VERSION ""

NS_ :

BS_:

BU_: XXX

BO_ 85 CID_LXWGIO: 8 XXX
 SG_ sig_nwyayb : 40|1@1+ (1,0) [0|1] "" XXX
 SG_ sig_ymgcwg : 56|8@1+ (1,0) [0|255] "" XXX

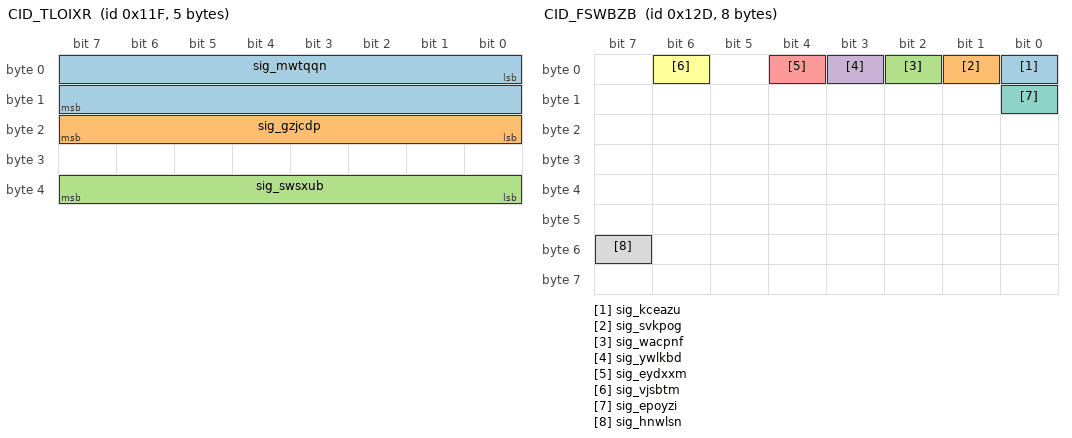
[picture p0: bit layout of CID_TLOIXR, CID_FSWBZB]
BO_ 287 CID_TLOIXR: 5 XXX
 SG_ sig_mwtqqn : 0|16@1- (0.1,0) [-450|450] "" XXX
 SG_ sig_gzjcdp : 16|8@1+ (4,0) [0|1020] "" XXX
 SG_ sig_swsxub : 32|8@1+ (1,0) [0|255] "" XXX

BO_ 289 CID_BDCPJX: 8 XXX
 SG_ sig_shysqb : 0|12@1+ (1,0) [0|255] "" XXX

BO_ 301 CID_FSWBZB: 8 XXX
 SG_ sig_kceazu : 0|1@0+ (1,0) [0|1] "" XXX
 SG_ sig_svkpog : 1|1@0+ (1,0) [0|1] "" XXX
 SG_ sig_wacpnf : 2|1@0+ (1,0) [0|1] "" XXX
 SG_ sig_ywlkbd : 3|1@0+ (1,0) [0|1] "" XXX
 SG_ sig_eydxxm : 4|1@0+ (1,0) [0|1] "" XXX
 SG_ sig_vjsbtm : 6|1@0+ (1,0) [0|1] "" XXX
 SG_ sig_epoyzi : 8|1@0+ (1,0) [0|1] "" XXX
 SG_ sig_hnwlsn : 55|1@0+ (1,0) [0|1] "" XXX

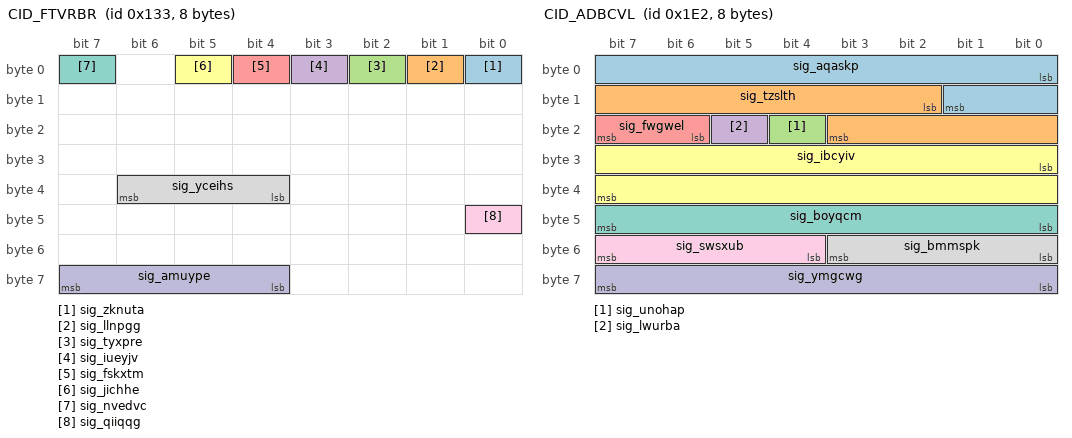
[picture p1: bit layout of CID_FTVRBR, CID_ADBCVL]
BO_ 307 CID_FTVRBR: 8 XXX
 SG_ sig_zknuta : 0|1@0+ (1,0) [0|1] "" XXX
 SG_ sig_llnpgg : 1|1@1+ (1,0) [0|1] "" XXX
 SG_ sig_tyxpre : 2|1@1+ (1,0) [0|1] "" XXX
 SG_ sig_iueyjv : 3|1@1+ (1,0) [0|1] "" XXX
 SG_ sig_fskxtm : 4|1@0+ (1,0) [0|1] "" XXX
 SG_ sig_jichhe : 5|1@0+ (1,0) [0|1] "" XXX
 SG_ sig_nvedvc : 7|1@0+ (1,0) [0|1] "" XXX
 SG_ sig_yceihs : 36|3@1+ (1,0) [0|7] "" XXX
 SG_ sig_qiiqqg : 40|1@0+ (1,0) [0|1] "" XXX
 SG_ sig_amuype : 63|4@0+ (1,0) [0|15] "" XXX

BO_ 482 CID_ADBCVL: 8 XXX
 SG_ sig_aqaskp : 0|10@1- (0.01,0) [0|5] "" XXX
 SG_ sig_tzslth : 10|10@1- (0.01,0) [-5|0] "" XXX
 SG_ sig_unohap : 20|1@0+ (1,0) [0|1] "" XXX
 SG_ sig_lwurba : 21|1@0+ (1,0) [0|1] "" XXX
 SG_ sig_fwgwel : 22|2@1+ (1,0) [0|1] "" XXX
 SG_ sig_ibcyiv : 24|16@1- (0.1,0) [-780|779.9] "" XXX
 SG_ sig_boyqcm : 47|8@0+ (1,0) [0|255] "" XXX
 SG_ sig_bmmspk : 48|4@1+ (1,0) [0|15] "" XXX
 SG_ sig_swsxub : 52|4@1+ (1,0) [0|15] "" XXX
 SG_ sig_ymgcwg : 56|8@1+ (1,0) [0|255] "" XXX

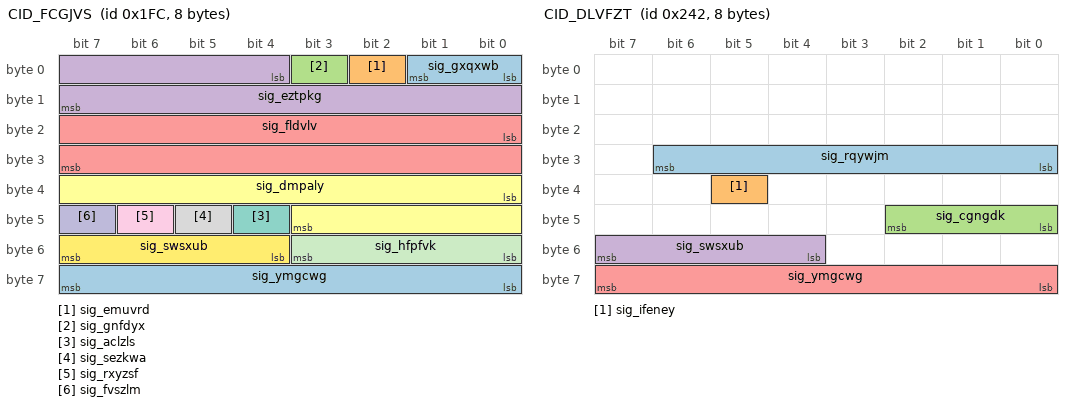
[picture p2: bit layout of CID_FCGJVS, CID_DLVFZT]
BO_ 508 CID_FCGJVS: 8 XXX
 SG_ sig_gxqxwb : 0|2@1+ (1,0) [0|1] "" XXX
 SG_ sig_emuvrd : 2|1@1+ (1,0) [0|1] "" XXX
 SG_ sig_gnfdyx : 3|1@0+ (1,0) [0|1] "" XXX
 SG_ sig_eztpkg : 4|12@1- (1,0) [-2048|2047] "" XXX
 SG_ sig_fldvlv : 16|16@1- (0.1,0) [-780|779.9] "Deg" XXX
 SG_ sig_dmpaly : 32|12@1- (0.01,0) [0|63] "" XXX
 SG_ sig_aclzls : 44|1@0+ (1,0) [0|1] "" XXX
 SG_ sig_sezkwa : 45|1@1+ (1,0) [0|255] "" XXX
 SG_ sig_rxyzsf : 46|1@1+ (1,0) [0|1] "" XXX
 SG_ sig_fvszlm : 47|1@0+ (1,0) [0|3] "" XXX
 SG_ sig_hfpfvk : 48|4@1+ (1,0) [0|15] "" XXX
 SG_ sig_swsxub : 52|4@1+ (1,0) [0|15] "" XXX
 SG_ sig_ymgcwg : 56|8@1+ (1,0) [0|255] "" XXX

BO_ 578 CID_DLVFZT: 8 XXX
 SG_ sig_rqywjm : 30|7@0+ (1,0) [0|127] "" XXX
 SG_ sig_ifeney : 37|1@0+ (1,0) [0|1] "" XXX
 SG_ sig_cgngdk : 40|3@1+ (1,0) [0|7] "" XXX
 SG_ sig_swsxub : 55|4@0+ (1,0) [0|15] "" XXX
 SG_ sig_ymgcwg : 56|8@1+ (1,0) [0|255] "" XXX

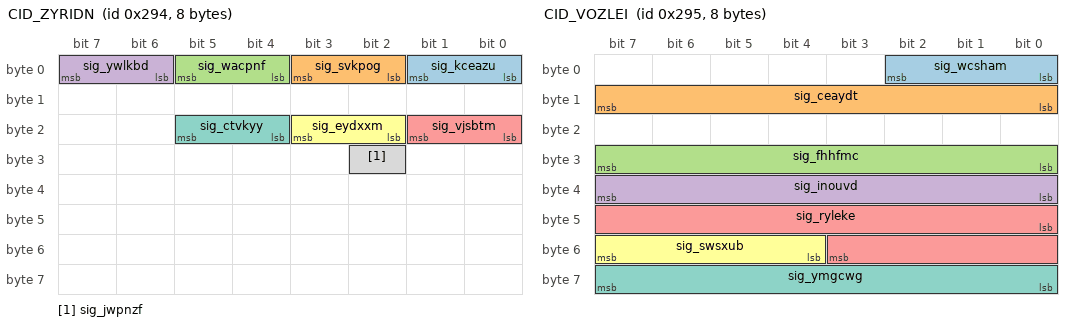
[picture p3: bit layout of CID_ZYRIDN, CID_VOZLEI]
BO_ 660 CID_ZYRIDN: 8 XXX
 SG_ sig_kceazu : 1|2@0+ (1,0) [0|3] "" XXX
 SG_ sig_svkpog : 3|2@0+ (1,0) [0|3] "" XXX
 SG_ sig_wacpnf : 5|2@0+ (1,0) [0|3] "" XXX
 SG_ sig_ywlkbd : 7|2@0+ (1,0) [0|3] "" XXX
 SG_ sig_vjsbtm : 17|2@0+ (1,0) [0|3] "" XXX
 SG_ sig_eydxxm : 19|2@0+ (1,0) [0|3] "" XXX
 SG_ sig_ctvkyy : 21|2@0+ (1,0) [0|3] "" XXX
 SG_ sig_jwpnzf : 26|1@0+ (1,0) [0|1] "" XXX

BO_ 661 CID_VOZLEI: 8 XXX
 SG_ sig_wcsham : 2|3@0+ (1,0) [0|7] "" XXX
 SG_ sig_ceaydt : 15|8@0+ (1,0) [0|255] "" XXX
 SG_ sig_fhhfmc : 31|8@0+ (1,0) [0|255] "" XXX
 SG_ sig_inouvd : 32|8@1+ (1,0) [0|255] "" XXX
 SG_ sig_ryleke : 40|12@1+ (1,0) [0|255] "" XXX
 SG_ sig_swsxub : 52|4@1+ (1,0) [0|15] "" XXX
 SG_ sig_ymgcwg : 63|8@0+ (1,0) [0|255] "" XXX

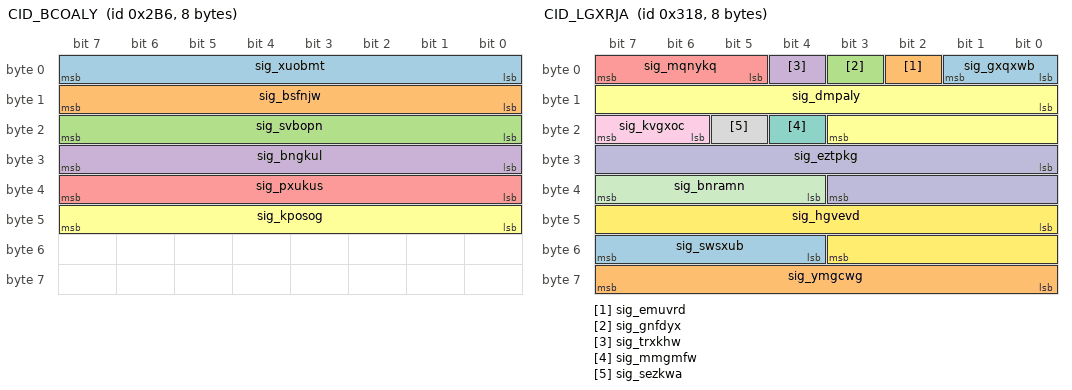
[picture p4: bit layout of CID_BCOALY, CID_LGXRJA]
BO_ 694 CID_BCOALY: 8 XXX
 SG_ sig_xuobmt : 7|8@0+ (1,0) [0|255] "" XXX
 SG_ sig_bsfnjw : 15|8@0+ (1,0) [0|255] "" XXX
 SG_ sig_svbopn : 23|8@0+ (1,0) [0|255] "" XXX
 SG_ sig_bngkul : 31|8@0+ (1,0) [0|255] "" XXX
 SG_ sig_pxukus : 39|8@0+ (1,0) [0|255] "" XXX
 SG_ sig_kposog : 47|8@0+ (1,0) [0|255] "" XXX

BO_ 790 CID_DHQGKZ: 8 XXX
 SG_ sig_uqectj : 3|4@0+ (1,0) [0|1] "" XXX
 SG_ sig_xvdwhm : 4|2@1+ (1,0) [0|3] "" XXX
 SG_ sig_fjcvei : 6|2@1+ (1,0) [0|3] "" XXX
 SG_ sig_chumhz : 8|2@1+ (1,0) [0|3] "" XXX
 SG_ sig_ohzual : 10|1@1+ (1,0) [0|1] "" XXX
 SG_ sig_bvykul : 11|4@1+ (1,0) [0|1] "" XXX
 SG_ sig_galhhk : 15|1@0+ (1,0) [0|1] "" XXX
 SG_ sig_ibcyiv : 16|11@1- (1,0) [-1024|1023] "" XXX
 SG_ sig_unohap : 27|1@1+ (1,0) [0|1] "" XXX
 SG_ sig_lwurba : 28|1@1+ (1,0) [0|3] "" XXX
 SG_ sig_wgjuut : 29|1@0+ (1,0) [0|1] "" XXX
 SG_ sig_dcycyc : 30|1@0+ (1,0) [0|1] "" XXX
 SG_ sig_psjqhq : 31|1@0+ (1,0) [0|1] "" XXX
 SG_ sig_evzzqz : 32|2@1+ (1,0) [0|3] "" XXX
 SG_ sig_ybwfcf : 34|2@1+ (1,0) [0|3] "" XXX
 SG_ sig_oikmge : 36|4@1+ (1,0) [0|3] "" XXX
 SG_ sig_phxivv : 40|8@1+ (5,-5) [-5|1270] "" XXX
 SG_ sig_brmnad : 49|2@0+ (1,0) [0|3] "" XXX
 SG_ sig_ltbnfk : 51|2@0+ (1,0) [0|3] "" XXX
 SG_ sig_swsxub : 52|4@1+ (1,0) [0|15] "" XXX
 SG_ sig_ymgcwg : 56|8@1+ (1,0) [0|15] "" XXX

BO_ 792 CID_LGXRJA: 8 XXX
 SG_ sig_gxqxwb : 0|2@1+ (1,0) [0|1] "" XXX
 SG_ sig_emuvrd : 2|1@1+ (1,0) [0|1] "" XXX
 SG_ sig_gnfdyx : 3|1@1+ (1,0) [0|1] "" XXX
 SG_ sig_trxkhw : 4|1@1+ (1,0) [0|1] "" XXX
 SG_ sig_mqnykq : 5|3@1+ (1,0) [0|1] "" XXX
 SG_ sig_dmpaly : 8|12@1- (1,0) [-2048|2047] "" XXX
 SG_ sig_mmgmfw : 20|1@1+ (1,0) [0|1] "" XXX
 SG_ sig_sezkwa : 21|1@1+ (1,0) [0|1] "" XXX
 SG_ sig_kvgxoc : 22|2@1+ (1,0) [0|15] "" XXX
 SG_ sig_eztpkg : 24|12@1- (1,0) [-2048|2047] "" XXX
 SG_ sig_bnramn : 36|4@1+ (1,0) [0|15] "" XXX
 SG_ sig_hgvevd : 40|12@1+ (1,0) [0|4095] "" XXX
 SG_ sig_swsxub : 52|4@1+ (1,0) [0|15] "" XXX
 SG_ sig_ymgcwg : 56|8@1+ (1,0) [0|255] "" XXX

BO_ 813 CID_SFVMZV: 8 XXX
 SG_ sig_dnezte : 0|9@1+ (0.5,0) [0|255.5] "" XXX
 SG_ sig_orbgxc : 9|1@1+ (1,0) [0|1] "" XXX
 SG_ sig_afblzn : 10|3@1+ (1,0) [0|7] "" XXX
 SG_ sig_wjzfkz : 13|3@1+ (1,0) [0|7] "" XXX
 SG_ sig_wufrel : 16|1@1+ (1,0) [0|1] "" XXX
 SG_ sig_fkuinh : 17|1@1+ (1,0) [0|1] "" XXX
 SG_ sig_gnfdyx : 18|1@1+ (1,0) [0|1] "" XXX
 SG_ sig_bsqawn : 19|3@1+ (1,0) [0|1] "" XXX
 SG_ sig_xayuaf : 22|1@0+ (1,0) [0|1] "" XXX
 SG_ sig_egtyql : 23|1@0+ (1,0) [0|1] "" XXX
 SG_ sig_chumhz : 24|1@1+ (1,0) [0|1] "" XXX
 SG_ sig_knckwp : 25|7@1+ (1,0) [0|127] "" XXX
 SG_ sig_oehrgc : 32|4@1+ (1,0) [0|15] "" XXX
 SG_ sig_mfvyng : 36|12@1+ (1,0) [0|4095] "" XXX
 SG_ sig_swsxub : 48|4@1+ (1,0) [0|15] "" XXX
 SG_ sig_qypfsa : 55|4@0+ (1,0) [0|15] "" XXX
 SG_ sig_ymgcwg : 56|8@1+ (1,0) [0|255] "" XXX

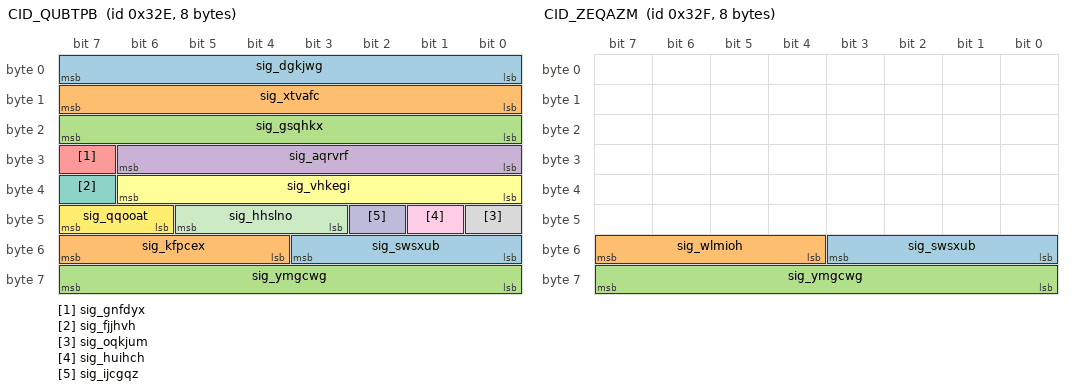
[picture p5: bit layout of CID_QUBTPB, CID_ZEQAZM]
BO_ 814 CID_QUBTPB: 8 XXX
 SG_ sig_dgkjwg : 0|8@1+ (0.05,-5) [-100|155] "" XXX
 SG_ sig_xtvafc : 8|8@1+ (0.05,-5) [0|1.26] "" XXX
 SG_ sig_gsqhkx : 16|8@1+ (0.05,-5) [0|1.26] "" XXX
 SG_ sig_aqrvrf : 24|7@1+ (0.2,0) [0|12.7] "" XXX
 SG_ sig_gnfdyx : 31|1@0+ (1,0) [0|1] "" XXX
 SG_ sig_vhkegi : 32|7@1+ (0.2,-16) [0|12.7] "" XXX
 SG_ sig_fjjhvh : 39|1@0+ (1,0) [0|1] "" XXX
 SG_ sig_oqkjum : 40|1@0+ (1,0) [0|1] "" XXX
 SG_ sig_huihch : 41|1@0+ (1,0) [0|1] "" XXX
 SG_ sig_ijcgqz : 42|1@1+ (1,0) [0|3] "" XXX
 SG_ sig_hhslno : 45|3@0+ (1,0) [0|1] "" XXX
 SG_ sig_qqooat : 46|2@1+ (1,0) [0|3] "" XXX
 SG_ sig_swsxub : 48|4@1+ (1,0) [0|15] "" XXX
 SG_ sig_kfpcex : 55|4@0+ (1,0) [0|15] "" XXX
 SG_ sig_ymgcwg : 56|8@1+ (1,0) [0|255] "" XXX

BO_ 815 CID_ZEQAZM: 8 XXX
 SG_ sig_swsxub : 48|4@1+ (1,0) [0|15] "" XXX
 SG_ sig_wlmioh : 55|4@0+ (1,0) [0|15] "" XXX
 SG_ sig_ymgcwg : 56|8@1+ (1,0) [0|255] "" XXX

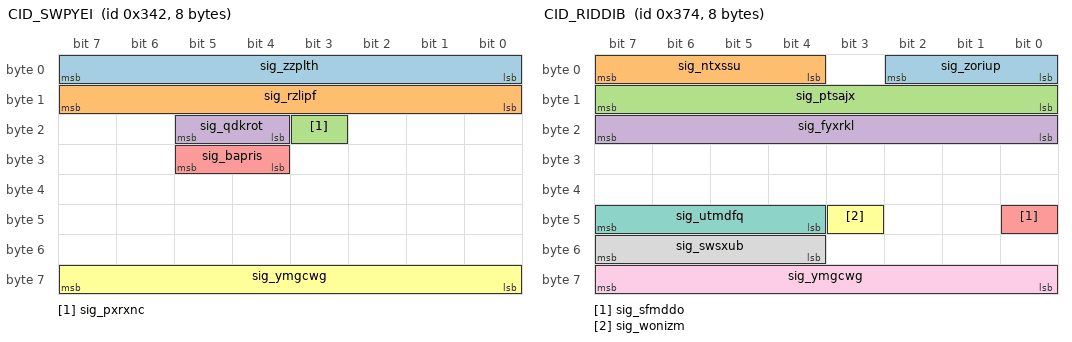
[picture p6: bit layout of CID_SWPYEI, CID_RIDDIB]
BO_ 834 CID_SWPYEI: 8 XXX
 SG_ sig_zzplth : 0|8@1+ (0.01,0) [0|2.55] "" XXX
 SG_ sig_rzlipf : 8|8@1+ (0.01,0) [0|2.55] "" XXX
 SG_ sig_pxrxnc : 19|1@1+ (1,0) [0|1] "" XXX
 SG_ sig_qdkrot : 20|2@1+ (1,0) [0|255] "" XXX
 SG_ sig_bapris : 28|2@1+ (1,0) [0|1] "" XXX
 SG_ sig_ymgcwg : 56|8@1+ (1,0) [0|255] "" XXX

 BO_ 884 CID_RIDDIB: 8 MRR
 SG_ sig_zoriup : 2|3@0+ (1,0) [0|3] "" MRR
 SG_ sig_ntxssu : 7|4@0+ (1,0) [0|15] "" MRR
 SG_ sig_ptsajx : 15|8@0+ (0.1,-12) [0|255] "" MRR
 SG_ sig_fyxrkl : 23|8@0+ (1,-100) [0|255] "" MRR
 SG_ sig_sfmddo : 40|1@0+ (1,0) [0|3] "" MRR
 SG_ sig_wonizm : 43|1@0+ (1,0) [0|1] "" XXX
 SG_ sig_utmdfq : 44|4@1+ (1,0) [0|15] "" XXX
 SG_ sig_swsxub : 52|4@1+ (1,0) [0|15] "" MRR
 SG_ sig_ymgcwg : 56|8@1+ (1,0) [0|255] "" MRR

BO_ 944 CID_QRZTUW: 8 XXX
 SG_ sig_rqmzij : 1|2@0+ (1,0) [0|3] "" XXX
 SG_ sig_wuihos : 2|1@0+ (1,0) [0|1] "" XXX
 SG_ sig_whrrti : 4|2@0+ (1,0) [0|3] "" XXX
 SG_ sig_fvrpri : 5|1@0+ (1,0) [0|1] "" XXX
 SG_ sig_tpdnyu : 6|1@0+ (1,0) [0|1] "" XXX
 SG_ sig_padbny : 7|1@0+ (1,0) [0|1] "" XXX
 SG_ sig_wdshpq : 8|1@0+ (1,0) [0|1] "" XXX
 SG_ sig_zzrjir : 11|3@0+ (1,0) [0|7] "" XXX
 SG_ sig_jgsenx : 12|1@0+ (1,0) [0|1] "" XXX
 SG_ sig_ctggnl : 14|2@0+ (1,0) [0|3] "" XXX
 SG_ sig_lutcdv : 15|1@0+ (1,0) [0|1] "" XXX
 SG_ sig_wncxxv : 16|1@0+ (1,0) [0|1] "" XXX
 SG_ sig_mlvdxa : 18|2@0+ (1,0) [0|3] "" XXX
 SG_ sig_dqrjdv : 19|1@0+ (1,0) [0|1] "" XXX
 SG_ sig_hvojhc : 23|4@0+ (1,0) [0|15] "" XXX
 SG_ sig_dskgew : 24|28@1+ (1,0) [0|268435455] "" XXX
 SG_ sig_swsxub : 52|4@1+ (1,0) [0|15] "" XXX
 SG_ sig_ymgcwg : 56|8@1+ (1,0) [0|255] "" XXX

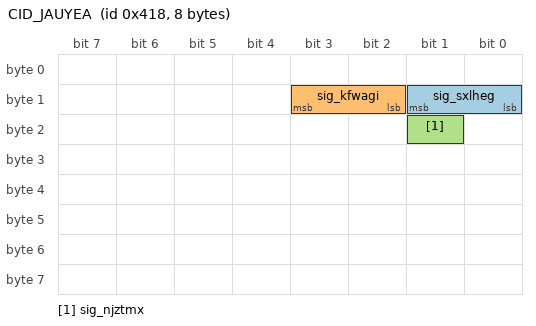
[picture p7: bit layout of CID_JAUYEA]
BO_ 1048 CID_JAUYEA: 8 XXX
 SG_ sig_sxlheg : 9|2@0+ (1,0) [0|1] "" XXX
 SG_ sig_kfwagi : 11|2@0+ (1,0) [0|1] "" XXX
 SG_ sig_njztmx : 17|1@0+ (1,0) [0|1] "" XXX

VAL_ 578 sig_cgngdk 4 "D" 2 "R" 3 "N" 1 "P";
VAL_ 790 sig_uqectj 11 "AutoFullBeamActive" 2 "AutoFullBeamInactive";
VAL_ 790 sig_xvdwhm 0 "GRAY" 1 "GREEN" 2 "YELLOW" 3 "RED";
VAL_ 790 sig_fjcvei 3 "ALARM_AND_LKA" 2 "LKA" 1 "ALARM" 0 "DISABLE";
VAL_ 790 sig_ybwfcf 0 "GRAY" 1 "GREEN" 2 "YELLOW" 3 "RED";
VAL_ 790 sig_brmnad 0 "VIBRATION" 1 "AUDIO" 2 "AUDIO_AND_VIBRATION";
VAL_ 792 sig_gxqxwb 0 "NotReady" 1 "Ready" 2 "Active" 3 "TemporaryFail";
VAL_ 813 sig_afblzn 4 "4BAR" 3 "3BAR" 2 "2BAR" 1 "1BAR";
VAL_ 813 sig_bsqawn 0 "OFF" 2 "ACC_ON" 3 "ACC_ACTIVE" 5 "FORCE_ACCEL" 7 "ERROR";
VAL_ 813 sig_knckwp 36 "ACC_ERROR" 22 "OVERRIDE" 12 "ENGAGE" 8 "DISENGAGE" 20 "ACC_ON" 32 "ACC_OFF" 48 "CHECK_GEAR_D" 16 "FORCE_ACCEL" 0 "NONE";
VAL_ 814 sig_hhslno 0 "Off" 1 "Passive" 2 "StandBy" 3 "ActiveControl" 4 "BrakeOnly" 5 "Override" 6 "Standstill" 7 "Failure";
VAL_ 814 sig_qqooat 0 "Softoff" 1 "Fastoff" 2 "Immediateoff" 3 "Initial";
VAL_ 834 sig_qdkrot 2 "SPORT" 1 "ECO" 0 "SNOW";
VAL_ 834 sig_bapris 3 "HEV" 2 "FORCE_EV" 1 "EV";
VAL_ 944 sig_whrrti 0 "NOTPRESSED" 1 "DOWN_SETSPEED" 3 "UP_RESETSPEED";
